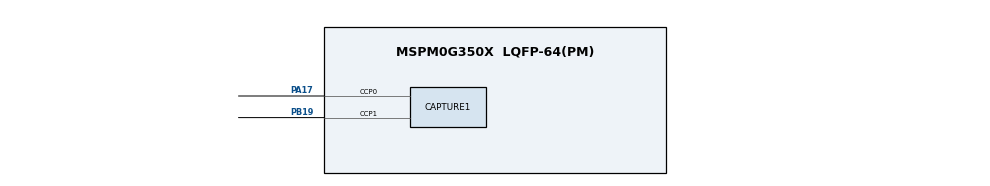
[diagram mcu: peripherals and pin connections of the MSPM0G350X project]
/**
 * @cliArgs --device "MSPM0G350X" --part "Default" --package "LQFP-64(PM)" --product "mspm0_sdk@2.11.00.07"
 * @versions {"tool":"1.26.2+4477"}
 */

/**
 * Import the modules used in this configuration.
 */
const CAPTURE  = scripting.addModule("/ti/driverlib/CAPTURE", {}, false);
const CAPTURE1 = CAPTURE.addInstance();
const SYSCTL   = scripting.addModule("/ti/driverlib/SYSCTL");

/**
 * Write custom configuration values to the imported modules.
 */
CAPTURE1.$name                      = "Encoder2";
CAPTURE1.ccIndex                    = 1;
CAPTURE1.timerClkPrescale           = 255;
CAPTURE1.captureInputMode           = "multi";
CAPTURE1.ccIndexMulti               = [0,1];
CAPTURE1.multi_countMode            = "DL_TIMER_COUNT_MODE_UP";
CAPTURE1.multi_countRep             = "DL_TIMER_REPEAT_MODE_ENABLED";
CAPTURE1.multi_cvae                 = "DL_TIMER_COUNT_AFTER_EN_ZERO";
CAPTURE1.multi_ch0_input_filter     = true;
CAPTURE1.multi_ch1_input_filter     = true;
CAPTURE1.interrupts                 = ["CC0_UP","CC1_UP"];
CAPTURE1.interruptPriority          = "2";
CAPTURE1.ccp0PinConfig.$name        = "ti_driverlib_gpio_GPIOPinGeneric0";
CAPTURE1.peripheral.$assign         = "TIMG7";
CAPTURE1.peripheral.ccp0Pin.$assign = "PA17";
CAPTURE1.peripheral.ccp1Pin.$assign = "PB19";
CAPTURE1.ccp1PinConfig.$name        = "ti_driverlib_gpio_GPIOPinGeneric1";

const Board = scripting.addModule("/ti/driverlib/Board", {}, false);

SYSCTL.forceDefaultClkConfig = true;

/**
 * Pinmux solution for unlocked pins/peripherals. This ensures that minor changes to the automatic solver in a future
 * version of the tool will not impact the pinmux you originally saw.  These lines can be completely deleted in order to
 * re-solve from scratch.
 */
Board.peripheral.$suggestSolution          = "DEBUGSS";
Board.peripheral.swclkPin.$suggestSolution = "PA20";
Board.peripheral.swdioPin.$suggestSolution = "PA19";
SYSCTL.peripheral.$suggestSolution         = "SYSCTL";
